# CTRL_MMR0_CFG0 register map
Vendor: Texas Instruments
Peripheral module from a debugger description file (folder am65x).
Registers are 32-bit, access per field, reset 0x8210007 unless marked. A register's access mark holds for its fields unless they carry their own. Offsets are as the file gives them; lines under a group give offsets from that group; [hi:lo] are bit positions; {n}, {i} and the like mark numbered series; 'fields as' and 'values as' point back to an identical list; <NAME> marks a mode.

## CTRL_MMR0_CFG0 (part 1 of 2)
0x00 CTRLMMR_PID ro reset 0x61800212 — Peripheral release details.
  [31:0] REV — TI internal data.
0x08 CTRLMMR_MMR_CFG1 ro reset 0x8000009F — Indicates the MMR configuration.
  [7:0] PARTITIONS — Indicates present partitions
0x30 CTRLMMR_MAIN_DEVSTAT reset 0x0 (reset mask 0xFFF80000) — Indicates SoC bootstrap selection. The default value of this register is determined by the SoC bootstrap pins when the por_boot_cfg_srst_n input is de-asserted. Note that this register will not be valid when returning from Deepsleep powerdown modes as the bootstrap pins are not relatched in this scenario.
  [18:0] BOOTMODE rw — Specifies the device Primary and Backup boot media.For more information, see
0x34 CTRLMMR_MAIN_BOOTCFG ro reset 0x0 (reset mask 0xFFF80000) — Indicates SoC bootstrap selection latched at power-on reset by PORz. The default value of this register is determined by the SoC bootstrap pins when the MMR por_boot_cfg_srst_n input is de-asserted and will remain until the SOC bootstrap pins are re-latched on a subsequent MMR por_boot_cfg_srst_n rising edge. Note that this register will not be valid when returning from Deepsleep powerdown modes as the bootstrap pins are not relatched in this scenario.
  [18:0] BOOTMODE — Specifies the device Primary and Backup boot media as latched at PORz
{0x50+4i} CTRLMMR_ICSSG{i}_DISABLE_STAT ro reset 0x0 (reset mask 0xFFFFFF00) (i=0..2) — Indicates disabled ICSSG{i} features.
  [7:0] DISABLE_STAT — ICSSG{i} feature disable status
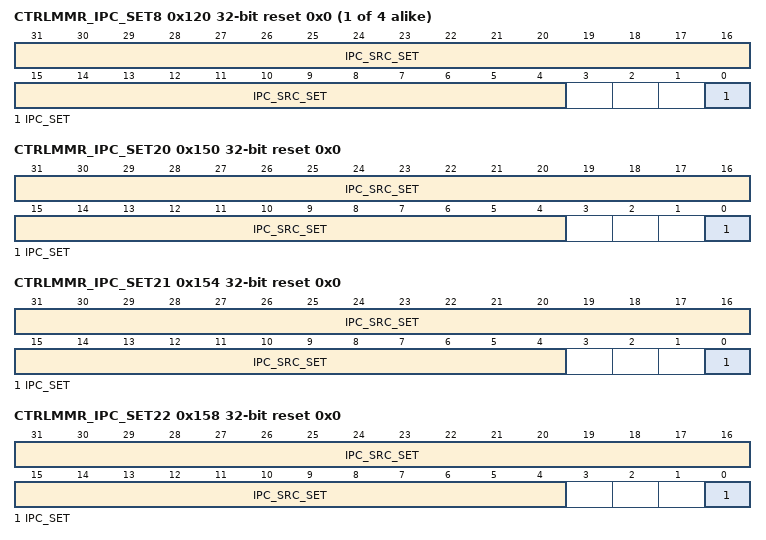
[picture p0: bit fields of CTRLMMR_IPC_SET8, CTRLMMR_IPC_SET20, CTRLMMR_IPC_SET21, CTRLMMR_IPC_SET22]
{0x100+4i} CTRLMMR_IPC_SET{i} access not given reset 0x0 (i=8..11) — Generate interprocessor communication interrupt to A5x core{i-8}.
  [31:4] IPC_SRC_SET — Read returns current value (access W1TS)
  [0] IPC_SET — Read returns 0 (access W1TS)
0x150 CTRLMMR_IPC_SET20 access not given reset 0x0 — Generate interprocessor communication interrupt to ICSSG0 PRU0.
  fields as CTRLMMR_IPC_SET8
0x154 CTRLMMR_IPC_SET21 access not given reset 0x0 — Generate interprocessor communication interrupt to ICSSG0 PRU1.
  fields as CTRLMMR_IPC_SET8
0x158 CTRLMMR_IPC_SET22 access not given reset 0x0 — Generate interprocessor communication interrupt to ICSSG1 PRU0.
  fields as CTRLMMR_IPC_SET8
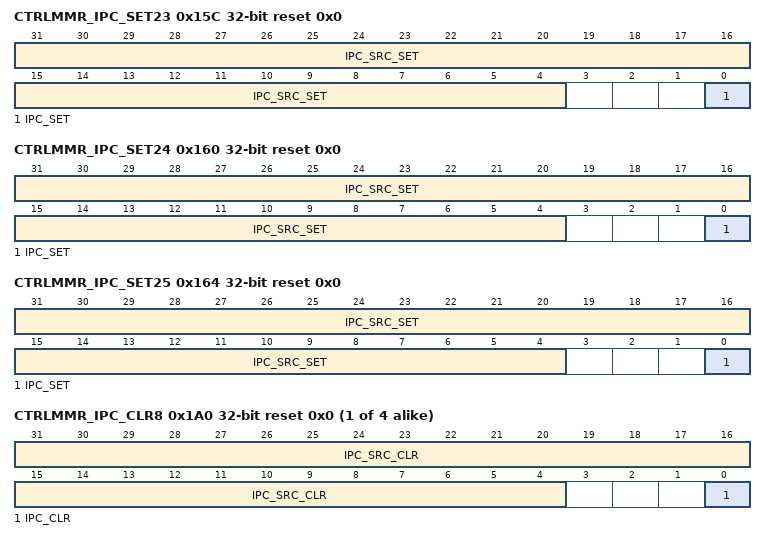
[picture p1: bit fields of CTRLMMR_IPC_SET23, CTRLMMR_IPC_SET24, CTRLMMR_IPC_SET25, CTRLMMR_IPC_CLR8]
0x15C CTRLMMR_IPC_SET23 access not given reset 0x0 — Generate interprocessor communication interrupt to ICSSG1 PRU1.
  fields as CTRLMMR_IPC_SET8
0x160 CTRLMMR_IPC_SET24 access not given reset 0x0 — Generate interprocessor communication interrupt to ICSSG2 PRU0.
  fields as CTRLMMR_IPC_SET8
0x164 CTRLMMR_IPC_SET25 access not given reset 0x0 — Generate interprocessor communication interrupt to ICSSG2 PRU1.
  fields as CTRLMMR_IPC_SET8
{0x180+4i} CTRLMMR_IPC_CLR{i} access not given reset 0x0 (i=8..11) — Acknowledge interprocessor communication interrupt to A5x core{i-8}.
  [31:4] IPC_SRC_CLR — Read returns current value (access W1TC)
  [0] IPC_CLR — Read returns current value (access W1TC)
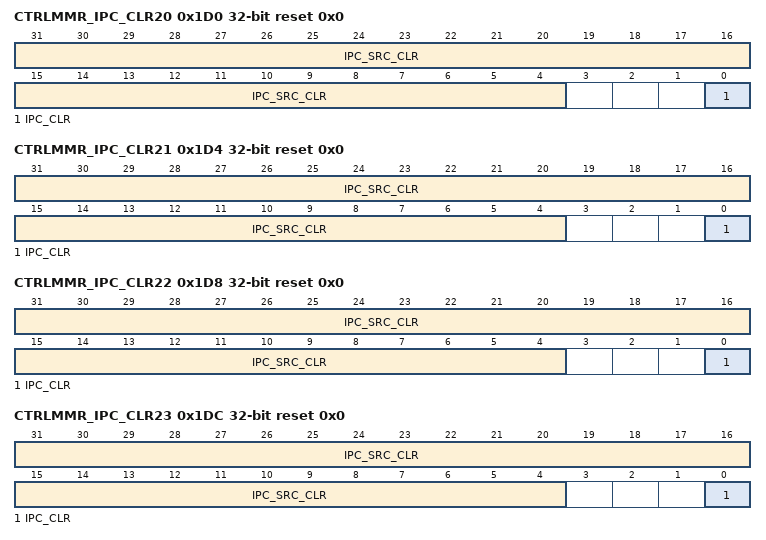
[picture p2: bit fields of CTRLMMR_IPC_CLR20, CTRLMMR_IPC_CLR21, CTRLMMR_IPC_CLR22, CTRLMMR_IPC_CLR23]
0x1D0 CTRLMMR_IPC_CLR20 access not given reset 0x0 — Acknowledge interprocessor communication interrupt to ICSSG0 PRU0.
  fields as CTRLMMR_IPC_CLR8
0x1D4 CTRLMMR_IPC_CLR21 access not given reset 0x0 — Acknowledge interprocessor communication interrupt to ICSSG0 PRU1.
  fields as CTRLMMR_IPC_CLR8
0x1D8 CTRLMMR_IPC_CLR22 access not given reset 0x0 — Acknowledge interprocessor communication interrupt to ICSSG1 PRU0.
  fields as CTRLMMR_IPC_CLR8
0x1DC CTRLMMR_IPC_CLR23 access not given reset 0x0 — Acknowledge interprocessor communication interrupt to ICSSG1 PRU1.
  fields as CTRLMMR_IPC_CLR8
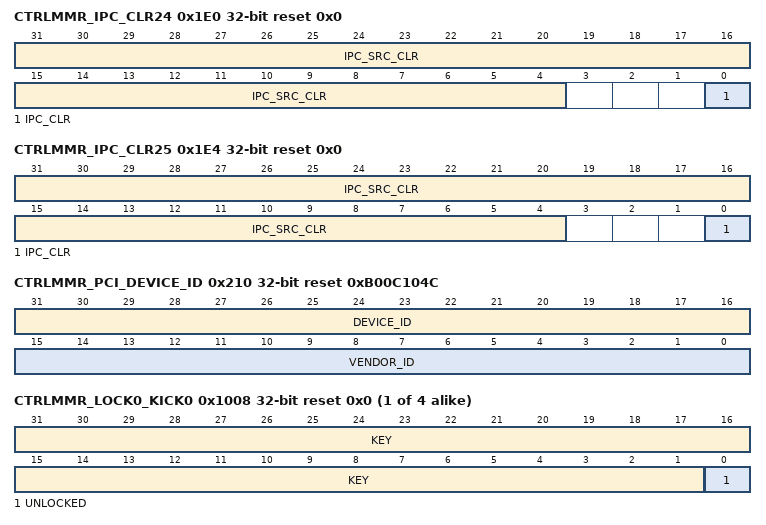
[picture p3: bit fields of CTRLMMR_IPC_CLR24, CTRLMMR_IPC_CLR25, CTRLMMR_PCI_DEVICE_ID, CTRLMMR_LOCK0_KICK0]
0x1E0 CTRLMMR_IPC_CLR24 access not given reset 0x0 — Acknowledge interprocessor communication interrupt to ICSSG2 PRU0.
  fields as CTRLMMR_IPC_CLR8
0x1E4 CTRLMMR_IPC_CLR25 access not given reset 0x0 — Acknowledge interprocessor communication interrupt to ICSSG2 PRU1.
  fields as CTRLMMR_IPC_CLR8
0x210 CTRLMMR_PCI_DEVICE_ID ro reset 0xB00C104C — PCIe device ID and vendor ID register.
  [31:16] DEVICE_ID
  [15:0] VENDOR_ID — TI Vendor ID
{0x1008+0x4000*i} CTRLMMR_LOCK{i}_KICK0 reset 0x0 (i=0..3) — Lower 32-bits of Partition{i} write lock key. This register must be written with the designated key value followed by a write to CTRLMMR_LOCK{i}_KICK1 with its key value before write-protected Partition {i} registers can be written.
  [31:1] KEY rw — Write the kick0 unlock value followed by the kick1 unlock value to unlock the write-protected Partition{i} registers
  [0] UNLOCKED ro — Unlock status. When set indicates that the proper unlock sequence has been performed and the partition is unlocked for writing.
{0x100C+0x4000*i} CTRLMMR_LOCK{i}_KICK1 rw reset 0x0 (i=0..3) — Upper 32-bits of Partition {i} write lock key. This register must be written with the designated key value after a write to CTRLMMR_LOCK{i}_KICK0 with its key value before write-protected Partition {i} registers can be written.
  [31:0] KEY — Write the kick1 unlock value after the kick0 unlock value to unlock the write-protected Partition{i} registers
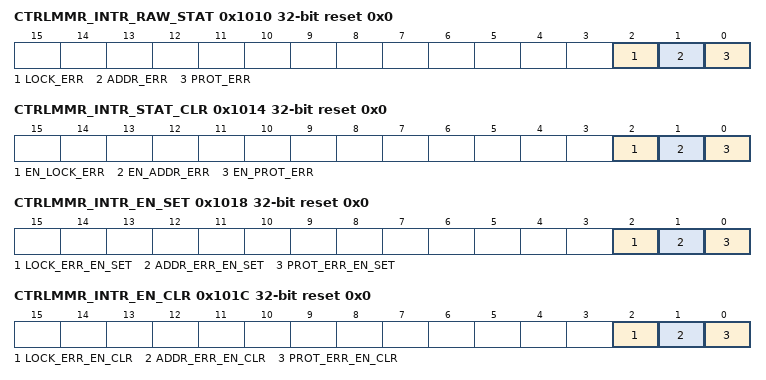
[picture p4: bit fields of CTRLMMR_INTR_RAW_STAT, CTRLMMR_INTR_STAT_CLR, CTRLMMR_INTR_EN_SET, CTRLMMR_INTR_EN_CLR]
0x1010 CTRLMMR_INTR_RAW_STAT access not given reset 0x0 — Shows the interrupt status (before enabling) and allows setting of the interrupt status (for test).
  [2] LOCK_ERR — Lock violation occurred (attempt to write a write-locked register with partition locked) (access W1TS)
  [1] ADDR_ERR — Address violation occurred (attempt to read or write an invalid register address) (access W1TS)
  [0] PROT_ERR — Protection violation occurred (attempt to read or write a register with insufficient security or privilege access rights) (access W1TS)
0x1014 CTRLMMR_INTR_STAT_CLR access not given reset 0x0 — Shows the enabled interrupt status and allows the interrupt to be cleared.
  [2] EN_LOCK_ERR — Enabled lock interrupt event status (access W1TC)
  [1] EN_ADDR_ERR — Enabled address interrupt event status (access W1TC)
  [0] EN_PROT_ERR — Enabled protection interrupt event status (access W1TC)
0x1018 CTRLMMR_INTR_EN_SET access not given reset 0x0 — Allows interrupt enables to be set.
  [2] LOCK_ERR_EN_SET — Lock interrupt enable (access W1TS)
  [1] ADDR_ERR_EN_SET — Address interrupt enable (access W1TS)
  [0] PROT_ERR_EN_SET — Protection interrupt enable (access W1TS)
0x101C CTRLMMR_INTR_EN_CLR access not given reset 0x0 — Allows interrupt enables to be cleared.
  [2] LOCK_ERR_EN_CLR — Lock interrupt disable (access W1TC)
  [1] ADDR_ERR_EN_CLR — Address interrupt disable (access W1TC)
  [0] PROT_ERR_EN_CLR — Protection interrupt disable (access W1TC)
0x1024 CTRLMMR_FAULT_ADDR ro reset 0x0 — Indicates the address of the first transfer that caused a fault to occur.
  [31:0] ADDRESS — Address of the faulted access
0x1028 CTRLMMR_FAULT_TYPE ro reset 0x0 — Indicates the access type of the first transfer that caused a fault to occur.
  [5:0] TYPE — Type of access which faulted 0h - No fault 1h - User execute access 2h - User write access 4h - User read access 8h - Supervisor execute access 10h - Supervisor write access 20h - Supervisor read access
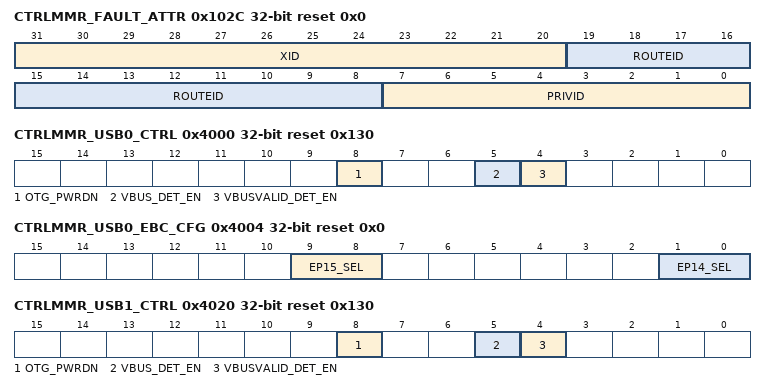
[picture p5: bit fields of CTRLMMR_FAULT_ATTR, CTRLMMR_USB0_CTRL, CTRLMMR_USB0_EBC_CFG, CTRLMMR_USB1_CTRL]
0x102C CTRLMMR_FAULT_ATTR ro reset 0x0 — Indicates the attributes of the first transfer that caused a fault to occur.
  [31:20] XID — Transaction ID
  [19:8] ROUTEID
  [7:0] PRIVID — Privilege ID
0x1030 CTRLMMR_FAULT_CLR access not given reset 0x0 — Allows software to clear the current fault Clearing the current fault allows the CTRLMMR_FAULT_ADDR, CTRLMMR_FAULT_TYPE, and CTRLMMR_FAULT_ATTR registers to latch the attributes of the next fault that occurs. This does not affect the fault interrupt event itself. The interrupt must be cleared using the appropriate INTR_STATUS_CLR register bits.
  [0] CLEAR — Fault clear (access W1TC)
0x4000 CTRLMMR_USB0_CTRL reset 0x130 — Controls USB0 operation.
  [8] OTG_PWRDN rw — Power down USB_VBUS_IDD0 module 0: powered up 1: powered down
  [5] VBUS_DET_EN rw — Global enable VBUS and ID detection for USB0 0: disabled 1: enabled
  [4] VBUSVALID_DET_EN rw — Enable VBUSVALID detection for USB0 0: disabled 1: enabled (needs VBUS_DET_EN = 1)
0x4004 CTRLMMR_USB0_EBC_CFG reset 0x0 — Configures the operation of the USB0 external buffer controls.See Trace Export via USB for more information about the trace over USB feature.
  [9:8] EP15_SEL rw — Endpoint 15 EBC control select 0h - Driven high 1h - Driven by MCU TBR DMA event 2h - Driven by MAIN TBR DMA event 3h - Driven by ComputeCluster TBR DMA event
  [1:0] EP14_SEL rw — Endpoint 14 EBC control select 0h - Driven high 1h - Driven by MCU TBR DMA event 2h - Driven by MAIN TBR DMA event 3h - Driven by ComputeCluster TBR DMA event
0x4020 CTRLMMR_USB1_CTRL reset 0x130 — Controls USB1 operation.
  [8] OTG_PWRDN rw — Power down USB_VBUS_IDD1 module 0: powered up 1: powered down
  [5] VBUS_DET_EN rw — Global enable VBUS and ID detection for USB1 0: disabled 1: enabled
  [4] VBUSVALID_DET_EN rw — Enable VBUSVALID detection for USB1 0: disabled 1: enabled (needs VBUS_DET_EN = 1)
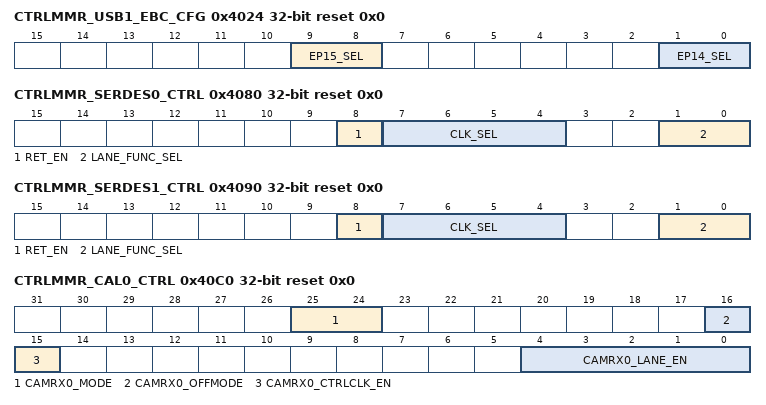
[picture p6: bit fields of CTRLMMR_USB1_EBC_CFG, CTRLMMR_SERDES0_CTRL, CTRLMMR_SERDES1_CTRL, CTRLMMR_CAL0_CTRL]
0x4024 CTRLMMR_USB1_EBC_CFG reset 0x0 — Configures the operation of the USB1 external buffer controls.See Trace Export via USB for more information about the trace over USB feature.
  fields as CTRLMMR_USB0_EBC_CFG
0x4060 CTRLMMR_PCIE0_CTRL reset 0x2 — Controls PCIe0 operation.
  [1:0] DEVICE_TYPE rw — Configures the PCIe interface operating mode 0h - Endpoint 1h - Legacy Endpoint 2h - Root Complex
0x4070 CTRLMMR_PCIE1_CTRL reset 0x2 — Controls PCIe1 operation.
  fields as CTRLMMR_PCIE0_CTRL
0x4080 CTRLMMR_SERDES0_CTRL reset 0x0 — Controls SERDES0 lane and clock assignment.
  [8] RET_EN rw — Retention enable
  [7:4] CLK_SEL rw — Selects the SERDES0 clock source
  [1:0] LANE_FUNC_SEL rw — Selects the SERDES0 lane function 0h - USB3 1h - PCIe0 Lane0 2h - ICSS2 SGMII Lane0
0x4090 CTRLMMR_SERDES1_CTRL reset 0x0 — Controls SERDES1 lane and clock assignment.
  [8] RET_EN rw — Retention enable
  [7:4] CLK_SEL rw — Selects the SERDES1 clock source
  [1:0] LANE_FUNC_SEL rw — Selects the SERDES1 lane function 0h - PCIe1 Lane0 1h - PCIe0 Lane1 2h - ICSS2 SGMII Lane1
0x40C0 CTRLMMR_CAL0_CTRL reset 0x0 — Controls Camera Adaptation Layer0 operation.
  [25:24] CAMRX0_MODE rw — Selects camera mode of operation 0h - DPHY mode 1h - CCP2 Data/Strobe mode 2h - CCP2 Data/Clock mode 3h - GP mode
  [16] CAMRX0_OFFMODE rw — When set, powers down the PHY analog circuits
  [15] CAMRX0_CTRLCLK_EN rw — CSI0 CTRLCLK enable
  [4:0] CAMRX0_LANE_EN rw — Lane enable bit for each CSI0 lane
0x40D0 CTRLMMR_DDR_STATUS ro reset 0x0 (reset mask 0xFFFFFFFE) — Indicates DDR status.
  [0] PLL_BYPASS — When set, indicates DDR PLL is bypassed.
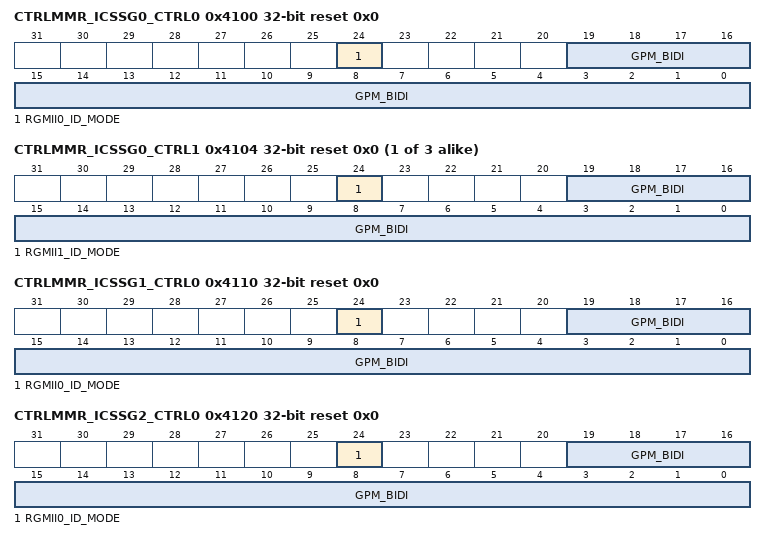
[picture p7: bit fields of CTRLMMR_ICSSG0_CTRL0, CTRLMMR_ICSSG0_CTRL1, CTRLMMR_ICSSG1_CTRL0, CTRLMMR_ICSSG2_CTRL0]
0x4100 CTRLMMR_ICSSG0_CTRL0 reset 0x0 — Controls ICSS_G0 operation.
  [24] RGMII0_ID_MODE rw — Controls the PRU_ICSSG0 RGMII0 port internal transmit delay
  [19:0] GPM_BIDI rw — Controls operation of the ICSS_G0 GPO0 pins. Each bit n controls the corresponding PRG0_PRU0GPOn I/O
{0x4104+0x10*i} CTRLMMR_ICSSG{i}_CTRL1 reset 0x0 (i=0..2) — Controls ICSS_G{i} operation.
  [24] RGMII1_ID_MODE rw — Controls the PRU_ICSSG{i} RGMII1 port internal transmit delay
  [19:0] GPM_BIDI rw — Controls operation of the ICSS_G{i} GPO0 pins. Each bit n controls the corresponding PRG{i}_PRU1GPOn I/O
0x4110 CTRLMMR_ICSSG1_CTRL0 reset 0x0 — Controls ICSS_G1 operation.
  [24] RGMII0_ID_MODE rw — Controls the PRU_ICSSG1 RGMII0 port internal transmit delay
  [19:0] GPM_BIDI rw — Controls operation of the ICSS_G1 GPO0 pins. Each bit n controls the corresponding PRG1_PRU0GPOn I/O
0x4120 CTRLMMR_ICSSG2_CTRL0 reset 0x0 — Controls ICSS_G2 operation.
  [24] RGMII0_ID_MODE rw — Controls the PRU_ICSSG2 RGMII0 port internal transmit delay
  [19:0] GPM_BIDI rw — Controls operation of the PRU_ICSSG2 GPO0 pins. Each bit n controls the corresponding PRG2_PRU0GPOn I/O
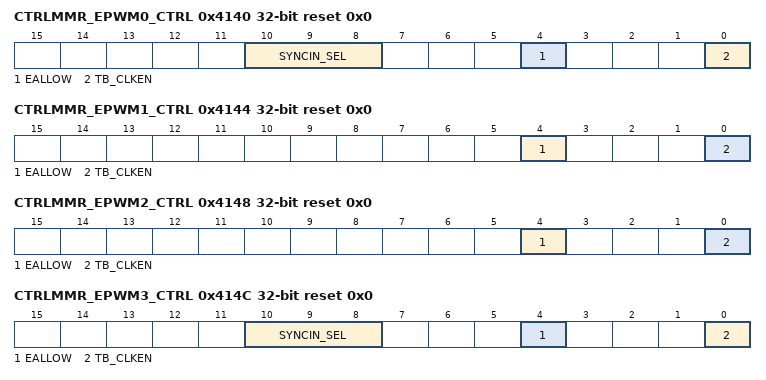
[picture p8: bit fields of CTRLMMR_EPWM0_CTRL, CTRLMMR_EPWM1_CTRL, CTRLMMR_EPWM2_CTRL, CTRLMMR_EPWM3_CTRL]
0x4140 CTRLMMR_EPWM0_CTRL reset 0x0 — Controls eHRPWM0 Operation.
  [10:8] SYNCIN_SEL rw — Selects the source of the PWM0 synchronization input 0h - PWM0_SYNCIN Pin 1h - None 2h - None 3h - None 4h - ICSSG0 Host Interrupt 6 5h - ICSSG1 Host Interrupt 6 6h - ICSSG2 Host Interrupt 6 7h - None
  [4] EALLOW rw — Enable write access to ePWM tripzone and HRPWM config registers
  [0] TB_CLKEN rw — Enable eHRPWM timebase clock
0x4144 CTRLMMR_EPWM1_CTRL reset 0x0 — Controls eHRPWM1 Operation.
  [4] EALLOW rw — Enable write access to ePWM tripzone and HRPWM config registers
  [0] TB_CLKEN rw — Enable eHRPWM timebase clock
0x4148 CTRLMMR_EPWM2_CTRL reset 0x0 — Controls eHRPWM2 Operation.
  fields as CTRLMMR_EPWM1_CTRL
0x414C CTRLMMR_EPWM3_CTRL reset 0x0 — Controls eHRPWM3 Operation.
  [10:8] SYNCIN_SEL rw — Selects the source of the PWM3 synchronization input 0h - PWM3_SYNCIN Pin 1h - PWM2 syncout signal, daisy chained 2h - None 3h - None 4h - ICSSG0 Host Interrupt 7 5h - ICSSG1 Host Interrupt 7 6h - ICSSG2 Host Interrupt 7 7h - None
  [4] EALLOW rw — Enable write access to ePWM tripzone and HRPWM config registers
  [0] TB_CLKEN rw — Enable eHRPWM timebase clock
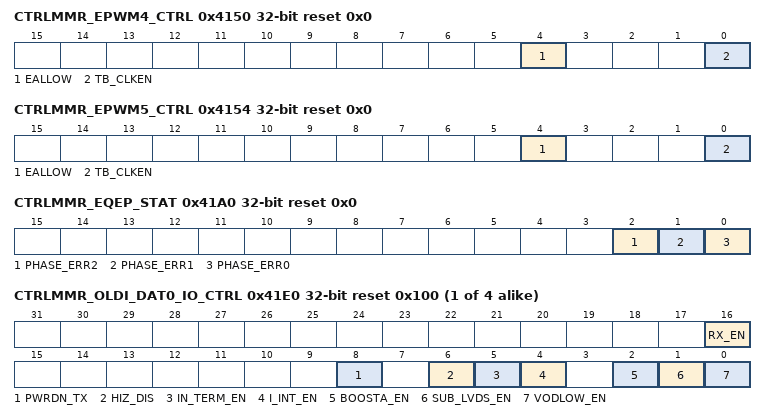
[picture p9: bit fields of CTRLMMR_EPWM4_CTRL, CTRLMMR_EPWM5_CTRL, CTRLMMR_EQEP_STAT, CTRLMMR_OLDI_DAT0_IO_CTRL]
0x4150 CTRLMMR_EPWM4_CTRL reset 0x0 — Controls eHRPWM4 Operation.
  fields as CTRLMMR_EPWM1_CTRL
0x4154 CTRLMMR_EPWM5_CTRL reset 0x0 — Controls eHRPWM5 Operation.
  fields as CTRLMMR_EPWM1_CTRL
0x4160 CTRLMMR_SOCA_SEL reset 0x0 — Selects Start of Conversion A output signal source. Each eHRPWM provides a SOCA event that can be used to trigger external ADCs. All eHRPWM SOCA events are ORed together allowing any of the 6 eHRPWMs to generate the event (if enabled within the eHRPWM). This event is then muxed with an ICSSx host interrupt allowing either an ICSSx or eHRPWMs to source the SOCA event pin.
  [1:0] SOCA_SEL rw — Selects the SOC A output source 0h - OR of all eHRPWM SOCA outputs 1h - ICSSG0 Host Interrupt 1 2h - ICSSG1 Host Interrupt 1 3h - ICSSG2 Host Interrupt 1
0x4164 CTRLMMR_SOCB_SEL reset 0x0 — Selects Start of Conversion B output signal source.. Each eHRPWM provides a SOCB event that can be used to trigger external ADCs. All eHRPWM SOCB events are ORed together allowing any of the 6 eHRPWMs to generate the event (if enabled within the eHRPWM). This event is then muxed with an ICSSx host interrupt allowing either an ICSSx or eHRPWMs to source the SOCB event pin.
  [1:0] SOCB_SEL rw — Selects the SOC B output source 0h - OR of all eHRPWM SOCB ouputs 1h - ICSSG0 Host Interrupt 2 2h - ICSSG1 Host Interrupt 2 3h - ICSSG2 Host Interrupt 2
0x41A0 CTRLMMR_EQEP_STAT ro reset 0x0 (reset mask 0xFFFFFFF8) — Displays status of EQEP modules.
  [2] PHASE_ERR2 — eQEP2 Phase error status
  [1] PHASE_ERR1 — eQEP1 Phase error status
  [0] PHASE_ERR0 — eQEP0 Phase error status
{0x41E0+4i} CTRLMMR_OLDI_DAT{i}_IO_CTRL reset 0x100 (i=0..3) — Controls the characteristics of the OLDI DATA IO.
  [16] RX_EN rw — Enable differential receiver (active high)
  [8] PWRDN_TX rw — Powerdown transmitter (active high)
  [6] HIZ_DIS rw — Disable Hi-Z on power down (pwrdn_tx = 1)
  [5] IN_TERM_EN rw — Enable internal termination (active high)
  [4] I_INT_EN rw — Both internal and external termination used
  [2] BOOSTA_EN rw — Enable fast rise/fall (active high)
  [1] SUB_LVDS_EN rw — Common mode Voltage selection
  [0] VODLOW_EN rw — Reduced differential output enable (active high)
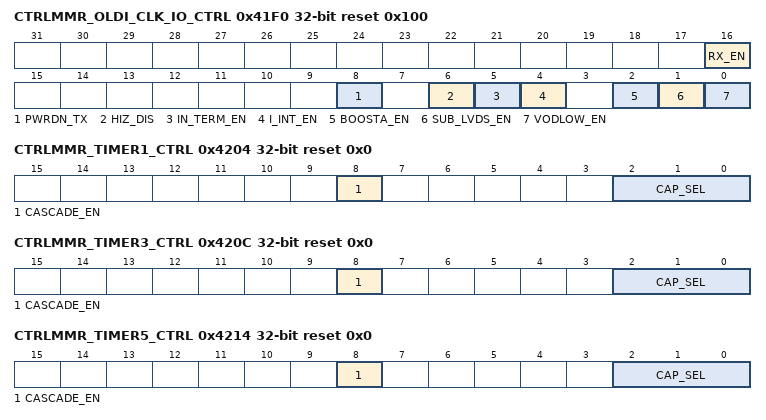
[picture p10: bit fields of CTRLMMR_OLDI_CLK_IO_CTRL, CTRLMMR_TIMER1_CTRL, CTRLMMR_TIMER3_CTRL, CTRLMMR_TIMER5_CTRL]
0x41F0 CTRLMMR_OLDI_CLK_IO_CTRL reset 0x100 — Controls the characteristics of the OLDI CLK IO.
  fields as CTRLMMR_OLDI_DAT0_IO_CTRL
0x4200 CTRLMMR_TIMER0_CTRL reset 0x0 — Controls TIMER0 operation.
  [2:0] CAP_SEL rw — Selects the TIMERIO input pin for capture input signal. This control is only used when TIMER0 is configured for capture operation.See 0h - Use TIMERIO0 pin 1h - Use TIMERIO1 pin 2h - Use TIMERIO2 pin 3h - Use TIMERIO3 pin 4h - Use TIMERIO4 pin 5h - Use TIMERIO5 pin 6h - Use TIMERIO6 pin 7h - Use TIMERIO7 pin
0x4204 CTRLMMR_TIMER1_CTRL reset 0x0 — Controls TIMER1 operation.
  [8] CASCADE_EN rw — Enables cascading of TIMER1 to TIMER0.Timer cascading is shown on
  [2:0] CAP_SEL rw — Selects the TIMERIO input pin for capture input signal. This control is only used when TIMER1 is configured for capture operation.See 0h - Use TIMERIO0 pin 1h - Use TIMERIO1 pin 2h - Use TIMERIO2 pin 3h - Use TIMERIO3 pin 4h - Use TIMERIO4 pin 5h - Use TIMERIO5 pin 6h - Use TIMERIO6 pin 7h - Use TIMERIO7 pin
0x4208 CTRLMMR_TIMER2_CTRL reset 0x0 — Controls TIMER2 operation.
  [2:0] CAP_SEL rw — Selects the TIMERIO input pin for capture input signal. This control is only used when TIMER2 is configured for capture operation.See 0h - Use TIMERIO0 pin 1h - Use TIMERIO1 pin 2h - Use TIMERIO2 pin 3h - Use TIMERIO3 pin 4h - Use TIMERIO4 pin 5h - Use TIMERIO5 pin 6h - Use TIMERIO6 pin 7h - Use TIMERIO7 pin
0x420C CTRLMMR_TIMER3_CTRL reset 0x0 — Controls TIMER3 operation.
  [8] CASCADE_EN rw — Enables cascading of TIMER3 to TIMER2Timer cascading is shown on
  [2:0] CAP_SEL rw — Selects the TIMERIO input pin for capture input signal. This control is only used when TIMER3 is configured for capture operation.See 0h - Use TIMERIO0 pin 1h - Use TIMERIO1 pin 2h - Use TIMERIO2 pin 3h - Use TIMERIO3 pin 4h - Use TIMERIO4 pin 5h - Use TIMERIO5 pin 6h - Use TIMERIO6 pin 7h - Use TIMERIO7 pin
0x4210 CTRLMMR_TIMER4_CTRL reset 0x0 — Controls TIMER4 operation.
  [2:0] CAP_SEL rw — Selects the TIMERIO input pin for capture input signal. This control is only used when TIMER4 is configured for capture operation.See 0h - Use TIMERIO0 pin 1h - Use TIMERIO1 pin 2h - Use TIMERIO2 pin 3h - Use TIMERIO3 pin 4h - Use TIMERIO4 pin 5h - Use TIMERIO5 pin 6h - Use TIMERIO6 pin 7h - Use TIMERIO7 pin
0x4214 CTRLMMR_TIMER5_CTRL reset 0x0 — Controls TIMER5 operation.
  [8] CASCADE_EN rw — Enables cascading of TIMER5 to TIMER4Timer cascading is shown on
  [2:0] CAP_SEL rw — Selects the TIMERIO input pin for capture input signal. This control is only used when TIMER5 is configured for capture operation.See 0h - Use TIMERIO0 pin 1h - Use TIMERIO1 pin 2h - Use TIMERIO2 pin 3h - Use TIMERIO3 pin 4h - Use TIMERIO4 pin 5h - Use TIMERIO5 pin 6h - Use TIMERIO6 pin 7h - Use TIMERIO7 pin
0x4218 CTRLMMR_TIMER6_CTRL reset 0x0 — Controls TIMER6 operation.
  [2:0] CAP_SEL rw — Selects the TIMERIO input pin for capture input signal. This control is only used when TIMER6 is configured for capture operation.See 0h - Use TIMERIO0 pin 1h - Use TIMERIO1 pin 2h - Use TIMERIO2 pin 3h - Use TIMERIO3 pin 4h - Use TIMERIO4 pin 5h - Use TIMERIO5 pin 6h - Use TIMERIO6 pin 7h - Use TIMERIO7 pin
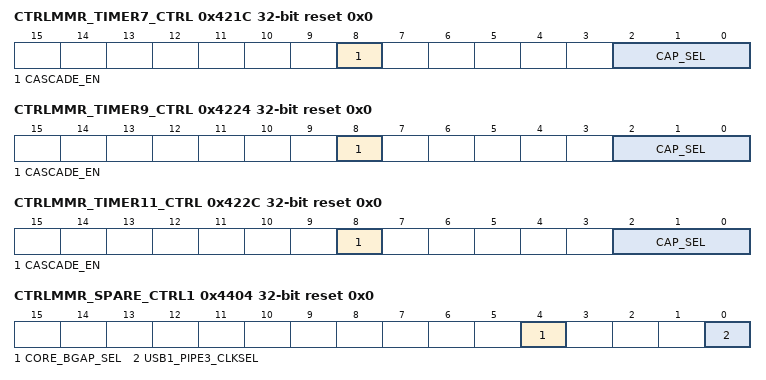
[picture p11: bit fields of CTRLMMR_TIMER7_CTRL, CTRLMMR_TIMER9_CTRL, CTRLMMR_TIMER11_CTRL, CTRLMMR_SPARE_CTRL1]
0x421C CTRLMMR_TIMER7_CTRL reset 0x0 — Controls TIMER7 operation.
  [8] CASCADE_EN rw — Enables cascading of TIMER7 to TIMER6Timer cascading is shown on
  [2:0] CAP_SEL rw — Selects the TIMERIO input pin for capture input signal. This control is only used when TIMER7 is configured for capture operation.See 0h - Use TIMERIO0 pin 1h - Use TIMERIO1 pin 2h - Use TIMERIO2 pin 3h - Use TIMERIO3 pin 4h - Use TIMERIO4 pin 5h - Use TIMERIO5 pin 6h - Use TIMERIO6 pin 7h - Use TIMERIO7 pin
0x4220 CTRLMMR_TIMER8_CTRL reset 0x0 — Controls TIMER8 operation.
  [2:0] CAP_SEL rw — Selects the TIMERIO input pin for capture input signal. This control is only used when TIMER8 is configured for capture operation.See 0h - Use TIMERIO0 pin 1h - Use TIMERIO1 pin 2h - Use TIMERIO2 pin 3h - Use TIMERIO3 pin 4h - Use TIMERIO4 pin 5h - Use TIMERIO5 pin 6h - Use TIMERIO6 pin 7h - Use TIMERIO7 pin
0x4224 CTRLMMR_TIMER9_CTRL reset 0x0 — Controls TIMER9 operation.
  [8] CASCADE_EN rw — Enables cascading of TIMER9 to TIMER8Timer cascading is shown on
  [2:0] CAP_SEL rw — Selects the TIMERIO input pin for capture input signal. This control is only used when TIMER9 is configured for capture operation.See 0h - Use TIMERIO0 pin 1h - Use TIMERIO1 pin 2h - Use TIMERIO2 pin 3h - Use TIMERIO3 pin 4h - Use TIMERIO4 pin 5h - Use TIMERIO5 pin 6h - Use TIMERIO6 pin 7h - Use TIMERIO7 pin
0x4228 CTRLMMR_TIMER10_CTRL reset 0x0 — Controls TIMER10 operation.
  [2:0] CAP_SEL rw — Selects the TIMERIO input pin for capture input signal. This control is only used when TIMER10 is configured for capture operation.See 0h - Use TIMERIO0 pin 1h - Use TIMERIO1 pin 2h - Use TIMERIO2 pin 3h - Use TIMERIO3 pin 4h - Use TIMERIO4 pin 5h - Use TIMERIO5 pin 6h - Use TIMERIO6 pin 7h - Use TIMERIO7 pin
0x422C CTRLMMR_TIMER11_CTRL reset 0x0 — Controls TIMER11 operation.
  [8] CASCADE_EN rw — Enables cascading of TIMER11 to TIMER10Timer cascading is shown on
  [2:0] CAP_SEL rw — Selects the TIMERIO input pin for capture input signal. This control is only used when TIMER11 is configured for capture operation.See 0h - Use TIMERIO0 pin 1h - Use TIMERIO1 pin 2h - Use TIMERIO2 pin 3h - Use TIMERIO3 pin 4h - Use TIMERIO4 pin 5h - Use TIMERIO5 pin 6h - Use TIMERIO6 pin 7h - Use TIMERIO7 pin
{0x4280+4i} CTRLMMR_TIMERIO{i}_CTRL reset 0x0 (i=0..7) — Controls Timer IO muxing.
  [3:0] OUT_SEL rw — Selects the source of the TIMERIO{i} outputSee 0h - TIMERIO{i} is driven by TIMER0 output 1h - TIMERIO{i} is driven by TIMER1 output 2h - TIMERIO{i} is driven by TIMER2 output 3h - TIMERIO{i} is driven by TIMER3 output 4h - TIMERIO{i} is driven by TIMER4 output 5h - TIMERIO{i} is driven by TIMER5 output 6h - TIMERIO{i} is driven by TIMER6 output 7h - TIMERIO{i} is driven by TIMER7 output 8h - TIMERIO{i} is driven by TIMER8 output 9h - TIMERIO{i} is driven by TIMER9 output Ah - TIMERIO{i} is driven by TIMER10 output Bh - TIMERIO{i} is driven by TIMER11 output
0x4404 CTRLMMR_SPARE_CTRL1 rw reset 0x0
  [4] CORE_BGAP_SEL — Core bandgap trim source select
  [0] USB1_PIPE3_CLKSEL — USB1 pipe3_txb_clk clock select
0x4800 CTRLMMR_SOCTBR_TRB0_W0 rw reset 0x8004000 — Software writable USB xHCI Transfer Request Block (TRB) 0 word0 for the SoC trace buffer transfer descriptor (TD). There are three TRBs in each TD. Each TRB consists of 4 consecutive 32-bit words (W[3:0]) defining the buffer address, buffer size and other control, as per the xHCI definition.See Trace Export via USB for more information about the trace over USB feature.
  [31:0] TRB_W0 — xHCI TRB 0 Word0
{0x4804+0x10*i} CTRLMMR_SOCTBR_TRB{i}_W1 rw reset 0x0 (i=0..2) — Software writable USB xHCI Transfer Request Block (TRB) {i} word1 for the SoC trace buffer transfer descriptor (TD). There are three TRBs in each TD. Each TRB consists of 4 consecutive 32-bit words (W[3:0]) defining the buffer address, buffer size and other control, as per the xHCI definition.See Trace Export via USB for more information about the trace over USB feature.
  [31:0] TRB_W1 — xHCI TRB {i} Word1
0x4808 CTRLMMR_SOCTBR_TRB0_W2 rw reset 0x1000 — Software writable USB xHCI Transfer Request Block (TRB) 0 word2 for the SoC trace buffer transfer descriptor (TD). There are three TRBs in each TD. Each TRB consists of 4 consecutive 32-bit words (W[3:0]) defining the buffer address, buffer size and other control, as per the xHCI definition.See Trace Export via USB for more information about the trace over USB feature.
  [31:0] TRB_W2 — xHCI TRB 0 Word2
0x480C CTRLMMR_SOCTBR_TRB0_W3 rw reset 0x11 — Software writable USB xHCI Transfer Request Block (TRB) 0 word3 for the SoC trace buffer transfer descriptor (TD). There are three TRBs in each TD. Each TRB consists of 4 consecutive 32-bit words (W[3:0]) defining the buffer address, buffer size and other control, as per the xHCI definition.See Trace Export via USB for more information about the trace over USB feature.
  [31:0] TRB_W3 — xHCI TRB 0 Word3
0x4810 CTRLMMR_SOCTBR_TRB1_W0 rw reset 0x8004000 — Software writable USB xHCI Transfer Request Block (TRB) 1 word0 for the SoC trace buffer transfer descriptor (TD). There are three TRBs in each TD. Each TRB consists of 4 consecutive 32-bit words (W[3:0]) defining the buffer address, buffer size and other control, as per the xHCI definition.See Trace Export via USB for more information about the trace over USB feature.
  [31:0] TRB_W0 — xHCI TRB 1 Word0
0x4818 CTRLMMR_SOCTBR_TRB1_W2 rw reset 0x1000 — Software writable USB xHCI Transfer Request Block (TRB) 1 word2 for the SoC trace buffer transfer descriptor (TD). There are three TRBs in each TD. Each TRB consists of 4 consecutive 32-bit words (W[3:0]) defining the buffer address, buffer size and other control, as per the xHCI definition.See Trace Export via USB for more information about the trace over USB feature.
  [31:0] TRB_W2 — xHCI TRB 1 Word2
0x481C CTRLMMR_SOCTBR_TRB1_W3 rw reset 0x11 — Software writable USB xHCI Transfer Request Block (TRB) 1 word3 for the SoC trace buffer transfer descriptor (TD). There are three TRBs in each TD. Each TRB consists of 4 consecutive 32-bit words (W[3:0]) defining the buffer address, buffer size and other control, as per the xHCI definition.See Trace Export via USB for more information about the trace over USB feature.
  [31:0] TRB_W3 — xHCI TRB 1 Word3
0x4820 CTRLMMR_SOCTBR_TRB2_W0 rw reset 0x104840 — Software writable USB xHCI Transfer Request Block (TRB) 2 word0 for the SoC trace buffer transfer descriptor (TD). There are three TRBs in each TD. Each TRB consists of 4 consecutive 32-bit words (W[3:0]) defining the buffer address, buffer size and other control, as per the xHCI definition.See Trace Export via USB for more information about the trace over USB feature.
  [31:0] TRB_W0 — xHCI TRB 2 Word0
0x4828 CTRLMMR_SOCTBR_TRB2_W2 rw reset 0x0 — Software writable USB xHCI Transfer Request Block (TRB) 2 word2 for the SoC trace buffer transfer descriptor (TD). There are three TRBs in each TD. Each TRB consists of 4 consecutive 32-bit words (W[3:0]) defining the buffer address, buffer size and other control, as per the xHCI definition.See Trace Export via USB for more information about the trace over USB feature.
  [31:0] TRB_W2 — xHCI TRB 2 Word2
0x482C CTRLMMR_SOCTBR_TRB2_W3 rw reset 0x81 — Software writable USB xHCI Transfer Request Block (TRB) 2 word3 for the SoC trace buffer transfer descriptor (TD). There are three TRBs in each TD. Each TRB consists of 4 consecutive 32-bit words (W[3:0]) defining the buffer address, buffer size and other control, as per the xHCI definition.See Trace Export via USB for more information about the trace over USB feature.
  [31:0] TRB_W3 — xHCI TRB 2 Word3
{0x4840+4i} CTRLMMR_SOCTBR_SHDW_TRB0_W{i} ro reset not defined (i=0..3) — xHC readable USB xHCI Transfer Request Block (TRB) 0 word{i} for the SoC trace buffer transfer descriptor (TD). Reflects the value contained in the corresponding CTRLMMR_SOCTBR_TRB0_W{i} register. Writes to this register are silently ignored (no error generated) allowing the xHC to continuously use the descriptor without software intervention to re-initialize the TRBs.See Trace Export via USB for more information about the trace over USB feature.
  [31:0] TRB_W{i} — xHCI TRB 0 Word{i}
{0x4850+4i} CTRLMMR_SOCTBR_SHDW_TRB1_W{i} ro reset not defined (i=0..3) — xHC readable USB xHCI Transfer Request Block (TRB) 1 word{i} for the SoC trace buffer transfer descriptor (TD). Reflects the value contained in the corresponding CTRLMMR_SOCTBR_TRB1_W{i} register. Writes to this register are silently ignored (no error generated) allowing the xHC to continuously use the descriptor without software intervention to re-initialize the TRBs.See Trace Export via USB for more information about the trace over USB feature.
  [31:0] TRB_W{i} — xHCI TRB 1 Word{i}
{0x4860+4i} CTRLMMR_SOCTBR_SHDW_TRB2_W{i} ro reset not defined (i=0..3) — xHC readable USB xHCI Transfer Request Block (TRB) 2 word{i} for the SoC trace buffer transfer descriptor (TD). Reflects the value contained in the corresponding CTRLMMR_SOCTBR_TRB2_W{i} register. Writes to this register are silently ignored (no error generated) allowing the xHC to continuously use the descriptor without software intervention to re-initialize the TRBs.See Trace Export via USB for more information about the trace over USB feature.
  [31:0] TRB_W{i} — xHCI TRB 2 Word{i}
